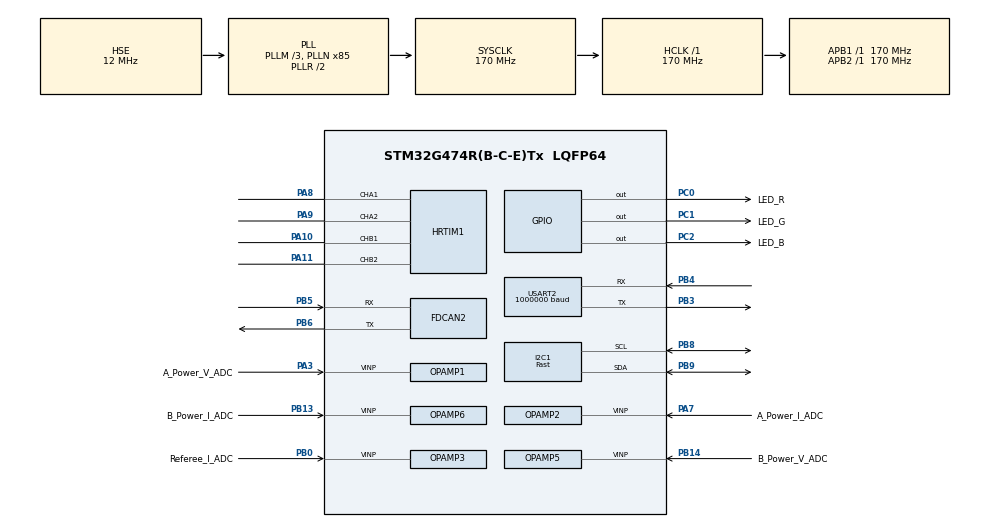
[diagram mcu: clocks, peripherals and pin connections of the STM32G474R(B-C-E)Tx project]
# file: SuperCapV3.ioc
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ADC1.Channel-0\#ChannelRegularConversion=ADC_CHANNEL_VOPAMP1
ADC1.ClockPrescaler=ADC_CLOCK_SYNC_PCLK_DIV4
ADC1.ContinuousConvMode=DISABLE
ADC1.DMAContinuousRequests=ENABLE
ADC1.EOCSelection=ADC_EOC_SINGLE_CONV
ADC1.ExternalTrigConv=ADC_EXTERNALTRIG_HRTIM_TRG1
ADC1.NbrOfConversionFlag=1
ADC1.OffsetNumber-0\#ChannelRegularConversion=ADC_OFFSET_NONE
ADC1.Rank-0\#ChannelRegularConversion=1
ADC1.SamplingTime-0\#ChannelRegularConversion=ADC_SAMPLETIME_3CYCLES_5
ADC1.master=1
ADC2.Channel-0\#ChannelRegularConversion=ADC_CHANNEL_VOPAMP2
ADC2.ClockPrescaler=ADC_CLOCK_SYNC_PCLK_DIV4
ADC2.ContinuousConvMode=DISABLE
ADC2.DMAContinuousRequests=ENABLE
ADC2.ExternalTrigConv=ADC_EXTERNALTRIG_HRTIM_TRG1
ADC2.NbrOfConversionFlag=1
ADC2.OffsetNumber-0\#ChannelRegularConversion=ADC_OFFSET_NONE
ADC2.Rank-0\#ChannelRegularConversion=1
ADC2.SamplingTime-0\#ChannelRegularConversion=ADC_SAMPLETIME_3CYCLES_5
ADC3.Channel-0\#ChannelRegularConversion=ADC_CHANNEL_VOPAMP3_ADC3
ADC3.ContinuousConvMode=DISABLE
ADC3.DMAContinuousRequests=ENABLE
ADC3.ExternalTrigConv=ADC_EXTERNALTRIG_HRTIM_TRG1
ADC3.NbrOfConversionFlag=1
ADC3.OffsetNumber-0\#ChannelRegularConversion=ADC_OFFSET_NONE
ADC3.Rank-0\#ChannelRegularConversion=1
ADC3.SamplingTime-0\#ChannelRegularConversion=ADC_SAMPLETIME_3CYCLES_5
ADC3.master=1
ADC4.Channel-0\#ChannelRegularConversion=ADC_CHANNEL_VOPAMP6
ADC4.ContinuousConvMode=DISABLE
ADC4.DMAContinuousRequests=ENABLE
ADC4.ExternalTrigConv=ADC_EXTERNALTRIG_HRTIM_TRG2
ADC4.LowPowerAutoWait=DISABLE
ADC4.NbrOfConversionFlag=1
ADC4.OffsetNumber-0\#ChannelRegularConversion=ADC_OFFSET_NONE
ADC4.Rank-0\#ChannelRegularConversion=1
ADC4.SamplingTime-0\#ChannelRegularConversion=ADC_SAMPLETIME_3CYCLES_5
ADC5.Channel-0\#ChannelRegularConversion=ADC_CHANNEL_VOPAMP5
ADC5.ContinuousConvMode=DISABLE
ADC5.DMAContinuousRequests=ENABLE
ADC5.ExternalTrigConv=ADC_EXTERNALTRIG_HRTIM_TRG2
ADC5.NbrOfConversion=1
ADC5.NbrOfConversionFlag=1
ADC5.OffsetNumber-0\#ChannelRegularConversion=ADC_OFFSET_NONE
ADC5.Rank-0\#ChannelRegularConversion=1
ADC5.SamplingTime-0\#ChannelRegularConversion=ADC_SAMPLETIME_3CYCLES_5
Dma.ADC1.0.Direction=DMA_PERIPH_TO_MEMORY
Dma.ADC1.0.EventEnable=DISABLE
Dma.ADC1.0.Instance=DMA1_Channel1
Dma.ADC1.0.MemDataAlignment=DMA_MDATAALIGN_HALFWORD
Dma.ADC1.0.MemInc=DMA_MINC_ENABLE
Dma.ADC1.0.Mode=DMA_CIRCULAR
Dma.ADC1.0.PeriphDataAlignment=DMA_PDATAALIGN_HALFWORD
Dma.ADC1.0.PeriphInc=DMA_PINC_DISABLE
Dma.ADC1.0.Polarity=HAL_DMAMUX_REQ_GEN_RISING
Dma.ADC1.0.Priority=DMA_PRIORITY_MEDIUM
Dma.ADC1.0.RequestNumber=1
Dma.ADC1.0.SignalID=NONE
Dma.ADC1.0.SyncEnable=DISABLE
Dma.ADC1.0.SyncPolarity=HAL_DMAMUX_SYNC_NO_EVENT
Dma.ADC1.0.SyncRequestNumber=1
Dma.ADC1.0.SyncSignalID=NONE
Dma.ADC2.1.Direction=DMA_PERIPH_TO_MEMORY
Dma.ADC2.1.EventEnable=DISABLE
Dma.ADC2.1.Instance=DMA1_Channel2
Dma.ADC2.1.MemDataAlignment=DMA_MDATAALIGN_HALFWORD
Dma.ADC2.1.MemInc=DMA_MINC_ENABLE
Dma.ADC2.1.Mode=DMA_CIRCULAR
Dma.ADC2.1.PeriphDataAlignment=DMA_PDATAALIGN_HALFWORD
Dma.ADC2.1.PeriphInc=DMA_PINC_DISABLE
Dma.ADC2.1.Polarity=HAL_DMAMUX_REQ_GEN_RISING
Dma.ADC2.1.Priority=DMA_PRIORITY_MEDIUM
Dma.ADC2.1.RequestNumber=1
Dma.ADC2.1.SignalID=NONE
Dma.ADC2.1.SyncEnable=DISABLE
Dma.ADC2.1.SyncPolarity=HAL_DMAMUX_SYNC_NO_EVENT
Dma.ADC2.1.SyncRequestNumber=1
Dma.ADC2.1.SyncSignalID=NONE
Dma.ADC3.2.Direction=DMA_PERIPH_TO_MEMORY
Dma.ADC3.2.EventEnable=DISABLE
Dma.ADC3.2.Instance=DMA1_Channel3
Dma.ADC3.2.MemDataAlignment=DMA_MDATAALIGN_HALFWORD
Dma.ADC3.2.MemInc=DMA_MINC_ENABLE
Dma.ADC3.2.Mode=DMA_CIRCULAR
Dma.ADC3.2.PeriphDataAlignment=DMA_PDATAALIGN_HALFWORD
Dma.ADC3.2.PeriphInc=DMA_PINC_DISABLE
Dma.ADC3.2.Polarity=HAL_DMAMUX_REQ_GEN_RISING
Dma.ADC3.2.Priority=DMA_PRIORITY_MEDIUM
Dma.ADC3.2.RequestNumber=1
Dma.ADC3.2.SignalID=NONE
Dma.ADC3.2.SyncEnable=DISABLE
Dma.ADC3.2.SyncPolarity=HAL_DMAMUX_SYNC_NO_EVENT
Dma.ADC3.2.SyncRequestNumber=1
Dma.ADC3.2.SyncSignalID=NONE
Dma.ADC4.3.Direction=DMA_PERIPH_TO_MEMORY
Dma.ADC4.3.EventEnable=DISABLE
Dma.ADC4.3.Instance=DMA1_Channel4
Dma.ADC4.3.MemDataAlignment=DMA_MDATAALIGN_HALFWORD
Dma.ADC4.3.MemInc=DMA_MINC_ENABLE
Dma.ADC4.3.Mode=DMA_CIRCULAR
Dma.ADC4.3.PeriphDataAlignment=DMA_PDATAALIGN_HALFWORD
Dma.ADC4.3.PeriphInc=DMA_PINC_DISABLE
Dma.ADC4.3.Polarity=HAL_DMAMUX_REQ_GEN_RISING
Dma.ADC4.3.Priority=DMA_PRIORITY_MEDIUM
Dma.ADC4.3.RequestNumber=1
Dma.ADC4.3.SignalID=NONE
Dma.ADC4.3.SyncEnable=DISABLE
Dma.ADC4.3.SyncPolarity=HAL_DMAMUX_SYNC_NO_EVENT
Dma.ADC4.3.SyncRequestNumber=1
Dma.ADC4.3.SyncSignalID=NONE
Dma.ADC5.4.Direction=DMA_PERIPH_TO_MEMORY
Dma.ADC5.4.EventEnable=DISABLE
Dma.ADC5.4.Instance=DMA1_Channel5
Dma.ADC5.4.MemDataAlignment=DMA_MDATAALIGN_HALFWORD
Dma.ADC5.4.MemInc=DMA_MINC_ENABLE
Dma.ADC5.4.Mode=DMA_CIRCULAR
Dma.ADC5.4.PeriphDataAlignment=DMA_PDATAALIGN_HALFWORD
Dma.ADC5.4.PeriphInc=DMA_PINC_DISABLE
Dma.ADC5.4.Polarity=HAL_DMAMUX_REQ_GEN_RISING
Dma.ADC5.4.Priority=DMA_PRIORITY_MEDIUM
Dma.ADC5.4.RequestNumber=1
Dma.ADC5.4.SignalID=NONE
Dma.ADC5.4.SyncEnable=DISABLE
Dma.ADC5.4.SyncPolarity=HAL_DMAMUX_SYNC_NO_EVENT
Dma.ADC5.4.SyncRequestNumber=1
Dma.ADC5.4.SyncSignalID=NONE
Dma.I2C1_TX.7.Direction=DMA_MEMORY_TO_PERIPH
Dma.I2C1_TX.7.EventEnable=DISABLE
Dma.I2C1_TX.7.Instance=DMA1_Channel8
Dma.I2C1_TX.7.MemDataAlignment=DMA_MDATAALIGN_BYTE
Dma.I2C1_TX.7.MemInc=DMA_MINC_ENABLE
Dma.I2C1_TX.7.Mode=DMA_NORMAL
Dma.I2C1_TX.7.PeriphDataAlignment=DMA_PDATAALIGN_BYTE
Dma.I2C1_TX.7.PeriphInc=DMA_PINC_DISABLE
Dma.I2C1_TX.7.Polarity=HAL_DMAMUX_REQ_GEN_RISING
Dma.I2C1_TX.7.Priority=DMA_PRIORITY_LOW
Dma.I2C1_TX.7.RequestNumber=1
Dma.I2C1_TX.7.SignalID=NONE
Dma.I2C1_TX.7.SyncEnable=DISABLE
Dma.I2C1_TX.7.SyncPolarity=HAL_DMAMUX_SYNC_NO_EVENT
Dma.I2C1_TX.7.SyncRequestNumber=1
Dma.I2C1_TX.7.SyncSignalID=NONE
Dma.Request0=ADC1
Dma.Request1=ADC2
Dma.Request2=ADC3
Dma.Request3=ADC4
Dma.Request4=ADC5
Dma.Request5=USART2_RX
Dma.Request6=USART2_TX
Dma.Request7=I2C1_TX
Dma.USART2_RX.5.Direction=DMA_PERIPH_TO_MEMORY
Dma.USART2_RX.5.EventEnable=DISABLE
Dma.USART2_RX.5.Instance=DMA1_Channel6
Dma.USART2_RX.5.MemDataAlignment=DMA_MDATAALIGN_BYTE
Dma.USART2_RX.5.MemInc=DMA_MINC_ENABLE
Dma.USART2_RX.5.Mode=DMA_NORMAL
Dma.USART2_RX.5.PeriphDataAlignment=DMA_PDATAALIGN_BYTE
Dma.USART2_RX.5.PeriphInc=DMA_PINC_DISABLE
Dma.USART2_RX.5.Polarity=HAL_DMAMUX_REQ_GEN_RISING
Dma.USART2_RX.5.Priority=DMA_PRIORITY_VERY_HIGH
Dma.USART2_RX.5.RequestNumber=1
Dma.USART2_RX.5.SignalID=NONE
Dma.USART2_RX.5.SyncEnable=DISABLE
Dma.USART2_RX.5.SyncPolarity=HAL_DMAMUX_SYNC_NO_EVENT
Dma.USART2_RX.5.SyncRequestNumber=1
Dma.USART2_RX.5.SyncSignalID=NONE
Dma.USART2_TX.6.Direction=DMA_MEMORY_TO_PERIPH
Dma.USART2_TX.6.EventEnable=DISABLE
Dma.USART2_TX.6.Instance=DMA1_Channel7
Dma.USART2_TX.6.MemDataAlignment=DMA_MDATAALIGN_BYTE
Dma.USART2_TX.6.MemInc=DMA_MINC_ENABLE
Dma.USART2_TX.6.Mode=DMA_NORMAL
Dma.USART2_TX.6.PeriphDataAlignment=DMA_PDATAALIGN_BYTE
Dma.USART2_TX.6.PeriphInc=DMA_PINC_DISABLE
Dma.USART2_TX.6.Polarity=HAL_DMAMUX_REQ_GEN_RISING
Dma.USART2_TX.6.Priority=DMA_PRIORITY_VERY_HIGH
Dma.USART2_TX.6.RequestNumber=1
Dma.USART2_TX.6.SignalID=NONE
Dma.USART2_TX.6.SyncEnable=DISABLE
Dma.USART2_TX.6.SyncPolarity=HAL_DMAMUX_SYNC_NO_EVENT
Dma.USART2_TX.6.SyncRequestNumber=1
Dma.USART2_TX.6.SyncSignalID=NONE
FDCAN2.AutoRetransmission=ENABLE
FDCAN2.CalculateBaudRateNominal=999999
FDCAN2.CalculateTimeBitNominal=1000
FDCAN2.CalculateTimeQuantumNominal=29.411764705882355
FDCAN2.DataPrescaler=17
FDCAN2.DataSyncJumpWidth=8
FDCAN2.DataTimeSeg1=5
FDCAN2.DataTimeSeg2=4
FDCAN2.ExtFiltersNbr=8
FDCAN2.NominalPrescaler=5
FDCAN2.NominalSyncJumpWidth=8
FDCAN2.NominalTimeSeg1=25
FDCAN2.NominalTimeSeg2=8
FDCAN2.StdFiltersNbr=28
HRTIM1.ADCTrigger1_Source1=HRTIM_ADCTRIGGEREVENT13_TIMERA_CMP4
HRTIM1.ADCTrigger2_Source1=HRTIM_ADCTRIGGEREVENT24_TIMERB_CMP4
HRTIM1.ADCTrigger_Id1=HRTIM_ADCTRIGGER_1
HRTIM1.ADCTrigger_Id2=HRTIM_ADCTRIGGER_2
HRTIM1.CompareUnit1-MasterTimer=HRTIM_COMPAREUNIT_1
HRTIM1.CompareUnit1-Output_TA1TA2=HRTIM_COMPAREUNIT_1
HRTIM1.CompareUnit1-Output_TB1TB2=HRTIM_COMPAREUNIT_1
HRTIM1.CompareUnit2-MasterTimer=__NULL
HRTIM1.CompareUnit2-Output_TA1TA2=__NULL
HRTIM1.CompareUnit3-MasterTimer=HRTIM_COMPAREUNIT_3
HRTIM1.CompareUnit3-Output_TA1TA2=HRTIM_COMPAREUNIT_3
HRTIM1.CompareUnit3-Output_TB1TB2=HRTIM_COMPAREUNIT_3
HRTIM1.CompareUnit4-Output_TA1TA2=HRTIM_COMPAREUNIT_4
HRTIM1.CompareUnit4-Output_TB1TB2=HRTIM_COMPAREUNIT_4
HRTIM1.CompareValue1-MasterTimer=0
HRTIM1.CompareValue1-Output_TA1TA2=0
HRTIM1.CompareValue1-Output_TB1TB2=0
HRTIM1.CompareValue3-MasterTimer=8000
HRTIM1.CompareValue3-Output_TA1TA2=12000
HRTIM1.CompareValue3-Output_TB1TB2=12000
HRTIM1.CompareValue4-Output_TA1TA2=14000
HRTIM1.CompareValue4-Output_TB1TB2=14000
HRTIM1.DeadTimeInsertion-Output_TA1TA2=HRTIM_TIMDEADTIMEINSERTION_ENABLED
HRTIM1.DeadTimeInsertion-Output_TB1TB2=HRTIM_TIMDEADTIMEINSERTION_ENABLED
HRTIM1.FallingValue-Output_TA1TA2=10
HRTIM1.FallingValue-Output_TB1TB2=10
HRTIM1.NumberADCTriggerSource1=1
HRTIM1.NumberADCTriggerSource2=1
HRTIM1.NumberResetSource1-Output_TA1TA2=1
HRTIM1.NumberResetSource1-Output_TB1TB2=1
HRTIM1.NumberResetTrigger-Output_TA1TA2=1
HRTIM1.NumberResetTrigger-Output_TB1TB2=1
HRTIM1.NumberSetSource1-Output_TA1TA2=1
HRTIM1.NumberSetSource1-Output_TB1TB2=1
HRTIM1.ORingUpdateSource_ADCTrigger1=HRTIM_ADCTRIGGERUPDATE_TIMER_A
HRTIM1.ORingUpdateSource_ADCTrigger2=HRTIM_ADCTRIGGERUPDATE_TIMER_B
HRTIM1.Periode_MASTER=16000
HRTIM1.Periode_TA=16000
HRTIM1.Periode_TB=16000
HRTIM1.PrescalerDead-Output_TA1TA2=HRTIM_TIMDEADTIME_PRESCALERRATIO_MUL4
HRTIM1.PrescalerDead-Output_TB1TB2=HRTIM_TIMDEADTIME_PRESCALERRATIO_MUL4
HRTIM1.ResetOutput1_Source1-Output_TA1TA2=HRTIM_OUTPUTRESET_TIMCMP3
HRTIM1.ResetOutput1_Source1-Output_TB1TB2=HRTIM_OUTPUTRESET_TIMCMP3
HRTIM1.ResetTrigger1-Output_TA1TA2=HRTIM_TIMRESETTRIGGER_MASTER_CMP1
HRTIM1.ResetTrigger1-Output_TB1TB2=HRTIM_TIMRESETTRIGGER_MASTER_CMP3
HRTIM1.RisingValue-Output_TA1TA2=10
HRTIM1.RisingValue-Output_TB1TB2=10
HRTIM1.SetOutput1_Source1-Output_TA1TA2=HRTIM_OUTPUTSET_TIMCMP1
HRTIM1.SetOutput1_Source1-Output_TB1TB2=HRTIM_OUTPUTSET_TIMCMP1
I2C1.I2C_Speed_Mode=I2C_Fast
I2C1.Timing=0x20824349
Mcu.Family=STM32G4
Mcu.Name=STM32G474R(B-C-E)Tx
Mcu.Package=LQFP64
NVIC.ADC1_2_IRQn=true\:2\:0\:false\:false\:true\:true\:true\:true
NVIC.ADC3_IRQn=true\:2\:0\:false\:false\:true\:true\:true\:true
NVIC.ADC4_IRQn=true\:2\:0\:false\:false\:true\:true\:true\:true
NVIC.DMA1_Channel1_IRQn=true\:0\:0\:false\:false\:true\:true\:true\:true
NVIC.DMA1_Channel6_IRQn=true\:2\:0\:false\:false\:true\:true\:true\:true
NVIC.DMA1_Channel7_IRQn=true\:2\:0\:false\:false\:true\:true\:true\:true
NVIC.DMA1_Channel8_IRQn=true\:2\:0\:false\:false\:true\:true\:true\:true
NVIC.FDCAN2_IT0_IRQn=true\:1\:0\:false\:false\:true\:true\:true\:true
NVIC.FDCAN2_IT1_IRQn=true\:1\:0\:false\:false\:true\:true\:true\:true
NVIC.I2C1_ER_IRQn=true\:2\:0\:false\:false\:true\:true\:true\:true
NVIC.I2C1_EV_IRQn=true\:2\:0\:false\:false\:true\:true\:true\:true
NVIC.PriorityGroup=NVIC_PRIORITYGROUP_4
NVIC.TIM6_DAC_IRQn=true\:0\:0\:false\:false\:true\:true\:true\:true
NVIC.TIM7_DAC_IRQn=true\:1\:0\:true\:false\:true\:true\:true\:true
NVIC.USART2_IRQn=true\:1\:0\:false\:false\:true\:true\:true\:true
OPAMP1.PowerMode=OPAMP_POWERMODE_HIGHSPEED
OPAMP2.PowerMode=OPAMP_POWERMODE_HIGHSPEED
OPAMP3.PowerMode=OPAMP_POWERMODE_HIGHSPEED
OPAMP5.PowerMode=OPAMP_POWERMODE_HIGHSPEED
OPAMP6.PowerMode=OPAMP_POWERMODE_HIGHSPEED
PA10.GPIO_Mode=GPIO_MODE_AF_PP
PA10.GPIO_PuPd=GPIO_NOPULL
PA10.GPIO_Speed_High_Default=GPIO_SPEED_FREQ_VERY_HIGH
PA10.Mode=Output_TB1TB2
PA10.Signal=HRTIM1_CHB1
PA11.GPIO_Mode=GPIO_MODE_AF_PP
PA11.GPIO_PuPd=GPIO_NOPULL
PA11.GPIO_Speed_High_Default=GPIO_SPEED_FREQ_VERY_HIGH
PA11.Mode=Output_TB1TB2
PA11.Signal=HRTIM1_CHB2
PA13.Mode=Serial_Wire
PA13.Signal=SYS_JTMS-SWDIO
PA14.Mode=Serial_Wire
PA14.Signal=SYS_JTCK-SWCLK
PA3.GPIO_Label=A_Power_V_ADC
PA3.Mode=Follower_Internally_Connected
PA3.Signal=OPAMP1_VINP
PA7.GPIO_Label=A_Power_I_ADC
PA7.Mode=Follower_Internally_Connected
PA7.Signal=OPAMP2_VINP
PA8.GPIO_Mode=GPIO_MODE_AF_PP
PA8.GPIO_PuPd=GPIO_NOPULL
PA8.GPIO_Speed_High_Default=GPIO_SPEED_FREQ_VERY_HIGH
PA8.Mode=Output_TA1TA2
PA8.Signal=HRTIM1_CHA1
PA9.GPIO_Mode=GPIO_MODE_AF_PP
PA9.GPIO_PuPd=GPIO_NOPULL
PA9.GPIO_Speed_High_Default=GPIO_SPEED_FREQ_VERY_HIGH
PA9.Mode=Output_TA1TA2
PA9.Signal=HRTIM1_CHA2
PB0.GPIO_Label=Referee_I_ADC
PB0.Mode=Follower_Internally_Connected
PB0.Signal=OPAMP3_VINP
PB13.GPIO_Label=B_Power_I_ADC
PB13.Mode=Follower_Internally_Connected
PB13.Signal=OPAMP6_VINP
PB14.GPIO_Label=B_Power_V_ADC
PB14.Mode=Follower_Internally_Connected
PB14.Signal=OPAMP5_VINP
PB3.GPIO_PuPd=GPIO_PULLUP
PB3.GPIO_Speed=GPIO_SPEED_FREQ_HIGH
PB3.Mode=Asynchronous
PB3.Signal=USART2_TX
PB4.GPIO_PuPd=GPIO_PULLUP
PB4.GPIO_Speed=GPIO_SPEED_FREQ_HIGH
PB4.Mode=Asynchronous
PB4.Signal=USART2_RX
PB5.Mode=FDCAN_Activate
PB5.Signal=FDCAN2_RX
PB6.Mode=FDCAN_Activate
PB6.Signal=FDCAN2_TX
PB8-BOOT0.GPIO_Pu=GPIO_PULLUP
PB8-BOOT0.Mode=I2C
PB8-BOOT0.Signal=I2C1_SCL
PB9.GPIO_Pu=GPIO_PULLUP
PB9.Mode=I2C
PB9.Signal=I2C1_SDA
PC0.GPIO_Label=LED_R
PC0.GPIO_ModeDefaultOutputPP=GPIO_MODE_OUTPUT_PP
PC0.GPIO_PuPd=GPIO_PULLUP
PC0.GPIO_Speed=GPIO_SPEED_FREQ_LOW
PC0.PinState=GPIO_PIN_SET
PC0.Signal=GPIO_Output
PC1.GPIO_Label=LED_G
PC1.GPIO_ModeDefaultOutputPP=GPIO_MODE_OUTPUT_PP
PC1.GPIO_PuPd=GPIO_PULLUP
PC1.GPIO_Speed=GPIO_SPEED_FREQ_LOW
PC1.PinState=GPIO_PIN_SET
PC1.Signal=GPIO_Output
PC2.GPIO_Label=LED_B
PC2.GPIO_ModeDefaultOutputPP=GPIO_MODE_OUTPUT_PP
PC2.GPIO_PuPd=GPIO_PULLUP
PC2.GPIO_Speed=GPIO_SPEED_FREQ_LOW
PC2.PinState=GPIO_PIN_SET
PC2.Signal=GPIO_Output
PF0-OSC_IN.Mode=HSE-External-Oscillator
PF0-OSC_IN.Signal=RCC_OSC_IN
PF1-OSC_OUT.Mode=HSE-External-Oscillator
PF1-OSC_OUT.Signal=RCC_OSC_OUT
ProjectManager.HeapSize=0x200
ProjectManager.StackSize=0x400
ProjectManager.TargetToolchain=MDK-ARM V5.32
RCC.ADC12Freq_Value=170000000
RCC.ADC345Freq_Value=170000000
RCC.AHBFreq_Value=170000000
RCC.APB1Freq_Value=170000000
RCC.APB1TimFreq_Value=170000000
RCC.APB2Freq_Value=170000000
RCC.APB2TimFreq_Value=170000000
RCC.CortexFreq_Value=170000000
RCC.EXTERNAL_CLOCK_VALUE=12288000
RCC.HCLKFreq_Value=170000000
RCC.HSE_VALUE=12000000
RCC.HSI48_VALUE=48000000
RCC.HSI_VALUE=16000000
RCC.LSE_VALUE=32768
RCC.PLLM=RCC_PLLM_DIV3
RCC.PLLN=85
RCC.PLLSourceVirtual=RCC_PLLSOURCE_HSE
RCC.SYSCLKFreq_VALUE=170000000
RCC.SYSCLKSource=RCC_SYSCLKSOURCE_PLLCLK
RCC.USBFreq_Value=170000000
RCC.VCOOutputFreq_Value=340000000
TIM6.PeriodNoDither=20-1
TIM6.Prescaler=170-1
TIM7.PeriodNoDither=1000-1
TIM7.Prescaler=170-1
USART2.BaudRate=1000000
USART2.SwapParam=ADVFEATURE_SWAP_DISABLE
USART2.VirtualMode-Asynchronous=VM_ASYNC
VP_ADC1_OPAMP_INTERNAL1.Mode=IN-OPAMP1
VP_ADC2_OPAMP_INTERNAL2.Mode=IN-OPAMP2
VP_ADC3_OPAMP_INTERNAL3.Mode=IN-OPAMP3
VP_ADC4_OPAMP_INTERNAL6.Mode=IN-OPAMP6
VP_ADC5_OPAMP_INTERNAL5.Mode=IN-OPAMP5
VP_HRTIM1_VS_hrtimMasterTimerNoOutput.Mode=MasterTimer
VP_SYS_VS_DBSignals.Mode=DisableDeadBatterySignals
VP_TIM6_VS_ClockSourceINT.Mode=Enable_Timer
VP_TIM7_VS_ClockSourceINT.Mode=Enable_Timer
board=custom

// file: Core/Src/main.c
/* USER CODE BEGIN Header */
/**
  ******************************************************************************
  * @file           : main.c
  * @brief          : Main program body
  ******************************************************************************
  * @attention
  *
  * Copyright (c) 2024 STMicroelectronics.
  * All rights reserved.
  *
  * This software is licensed under terms that can be found in the LICENSE file
  * in the root directory of this software component.
  * If no LICENSE file comes with this software, it is provided AS-IS.
  *
  ******************************************************************************
  */
/* USER CODE END Header */
#include "main.h"
#include "adc.h"
#include "dma.h"
#include "fdcan.h"
#include "hrtim.h"
#include "i2c.h"
#include "opamp.h"
#include "tim.h"
#include "usart.h"
#include "gpio.h"

/* USER CODE BEGIN Includes */
/* App 层的头文件统一由 main.h 引入 */
/* USER CODE END Includes */

/* USER CODE BEGIN PV */
/* 应用层状态全部在 App/ 内维护 */
/* USER CODE END PV */

void SystemClock_Config(void);

int main(void)
{

  /* MCU Configuration--------------------------------------------------------*/

  /* Reset of all peripherals, Initializes the Flash interface and the Systick. */
  HAL_Init();

  /* Configure the system clock */
  SystemClock_Config();

  /* Initialize all configured peripherals */
  MX_GPIO_Init();
  MX_DMA_Init();
  MX_ADC1_Init();
  MX_ADC2_Init();
  MX_ADC3_Init();
  MX_ADC4_Init();
  MX_ADC5_Init();
  MX_OPAMP1_Init();
  MX_OPAMP2_Init();
  MX_OPAMP3_Init();
  MX_OPAMP5_Init();
  MX_OPAMP6_Init();
  MX_FDCAN2_Init();
  MX_HRTIM1_Init();
  MX_TIM6_Init();
  MX_TIM7_Init();
  MX_USART2_UART_Init();
  MX_I2C1_Init();
  /* USER CODE BEGIN 2 */
    HAL_Delay(300);
  /* USER CODE END 2 */

  /* Infinite loop */
  /* USER CODE BEGIN WHILE */
    HAL_Delay(100);
    App_Init();

    while (1)
    {
        App_Loop();

    /* USER CODE END WHILE */

  }
}

void SystemClock_Config(void)
{
  RCC_OscInitTypeDef RCC_OscInitStruct = {0};
  RCC_ClkInitTypeDef RCC_ClkInitStruct = {0};

  /** Configure the main internal regulator output voltage
  */
  HAL_PWREx_ControlVoltageScaling(PWR_REGULATOR_VOLTAGE_SCALE1_BOOST);

  /** Initializes the RCC Oscillators according to the specified parameters
  * in the RCC_OscInitTypeDef structure.
  */
  RCC_OscInitStruct.OscillatorType = RCC_OSCILLATORTYPE_HSE;
  RCC_OscInitStruct.HSEState = RCC_HSE_ON;
  RCC_OscInitStruct.PLL.PLLState = RCC_PLL_ON;
  RCC_OscInitStruct.PLL.PLLSource = RCC_PLLSOURCE_HSE;
  RCC_OscInitStruct.PLL.PLLM = RCC_PLLM_DIV3;
  RCC_OscInitStruct.PLL.PLLN = 85;
  RCC_OscInitStruct.PLL.PLLP = RCC_PLLP_DIV2;
  RCC_OscInitStruct.PLL.PLLQ = RCC_PLLQ_DIV2;
  RCC_OscInitStruct.PLL.PLLR = RCC_PLLR_DIV2;
  if (HAL_RCC_OscConfig(&RCC_OscInitStruct) != HAL_OK)
  {
    Error_Handler();
  }

  /** Initializes the CPU, AHB and APB buses clocks
  */
  RCC_ClkInitStruct.ClockType = RCC_CLOCKTYPE_HCLK|RCC_CLOCKTYPE_SYSCLK
                              |RCC_CLOCKTYPE_PCLK1|RCC_CLOCKTYPE_PCLK2;
  RCC_ClkInitStruct.SYSCLKSource = RCC_SYSCLKSOURCE_PLLCLK;
  RCC_ClkInitStruct.AHBCLKDivider = RCC_SYSCLK_DIV1;
  RCC_ClkInitStruct.APB1CLKDivider = RCC_HCLK_DIV1;
  RCC_ClkInitStruct.APB2CLKDivider = RCC_HCLK_DIV1;

  if (HAL_RCC_ClockConfig(&RCC_ClkInitStruct, FLASH_LATENCY_4) != HAL_OK)
  {
    Error_Handler();
  }
}

void Error_Handler(void)
{
  __disable_irq();
  while (1)
  {
  }
}
